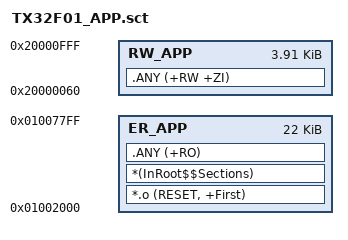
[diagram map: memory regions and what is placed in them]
; ============================================================
;  Application scatter file（替换 USER 工程原来的 .sct）
;    APP Flash: 0x01002000 - 0x010077FF   (22 KB)
;    SRAM     : 0x20000060 - 0x20000FFF   (前 96B 是 BL 的软向量表)
; ============================================================

LR_APP 0x01002000 0x00005800  {
  ER_APP 0x01002000 0x00005800  {
    *.o (RESET, +First)
    *(InRoot$$Sections)
    .ANY (+RO)
  }
  RW_APP 0x20000060 0x00000FA0  {
    .ANY (+RW +ZI)
  }
}
